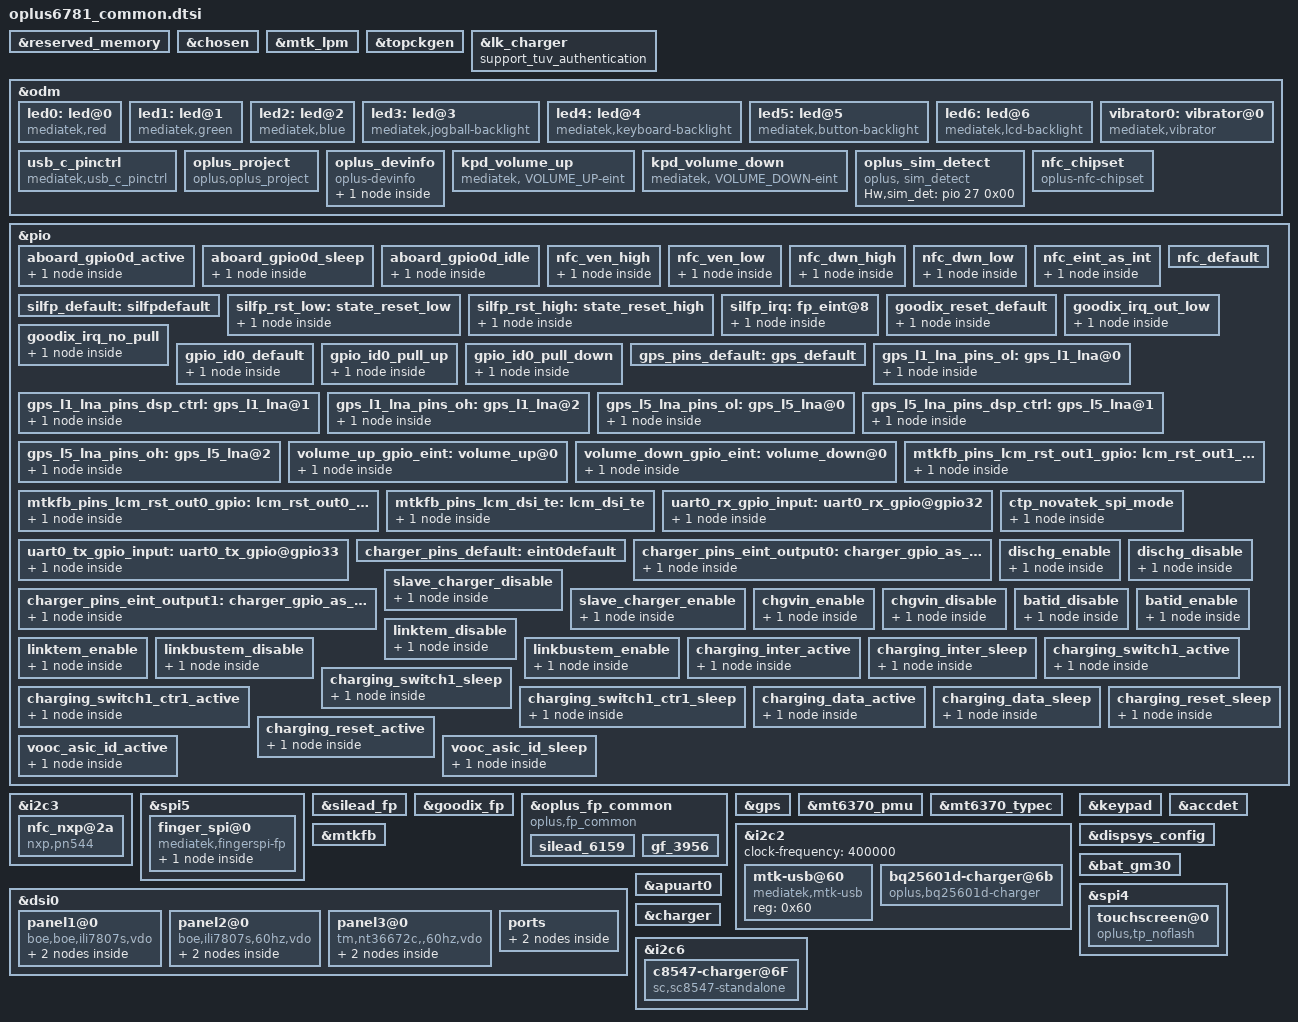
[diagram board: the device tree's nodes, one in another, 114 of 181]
/*
 * Copyright (C) 2015 MediaTek Inc.
 *
 * This program is free software: you can redistribute it and/or modify
 * it under the terms of the GNU General Public License version 2 as
 * published by the Free Software Foundation.
 *
 * This program is distributed in the hope that it will be useful,
 * but WITHOUT ANY WARRANTY; without even the implied warranty of
 * MERCHANTABILITY or FITNESS FOR A PARTICULAR PURPOSE. See the
 * GNU General Public License for more details.
 */
#include <dt-bindings/interrupt-controller/irq.h>
#include <dt-bindings/interrupt-controller/arm-gic.h>
#include <dt-bindings/pinctrl/mt6781-pinfunc.h>

&reserved_memory {
};

/* chosen */
&chosen {
	/* fpga may has no lk, we need to specify display info here */
	/* fb buffer is reserved using this dts by memory node above */
	atag,videolfb-fb_base_l = <0x7e605000>;
	atag,videolfb-fb_base_h = <0x0>;
	atag,videolfb-islcmfound = <1>;
	atag,videolfb-islcm_inited = <0>;
	atag,videolfb-fps= <6000>;
	atag,videolfb-vramSize= <0x017e8000>;
	atag,videolfb-lcmname=
		"nt35695_fhd_dsi_cmd_truly_rt5081_drv";
};

&mtk_lpm {
};

&topckgen {
};

&lk_charger {
	support_tuv_authentication;
};

&odm {
	led0:led@0 {
		compatible = "mediatek,red";
		led_mode = <0>;
		data = <1>;
		pwm_config = <0 0 0 0 0>;
	};
	led1:led@1 {
		compatible = "mediatek,green";
		led_mode = <0>;
		data = <1>;
		pwm_config = <0 0 0 0 0>;
	};
	led2:led@2 {
		compatible = "mediatek,blue";
		led_mode = <0>;
		data = <1>;
		pwm_config = <0 0 0 0 0>;
	};
	led3:led@3 {
		compatible = "mediatek,jogball-backlight";
		led_mode = <0>;
		data = <1>;
		pwm_config = <0 0 0 0 0>;
	};
	led4:led@4 {
		compatible = "mediatek,keyboard-backlight";
		led_mode = <0>;
		data = <1>;
		pwm_config = <0 0 0 0 0>;
	};
	led5:led@5 {
		compatible = "mediatek,button-backlight";
		led_mode = <0>;
		data = <1>;
		pwm_config = <0 0 0 0 0>;
	};
	led6:led@6 {
		compatible = "mediatek,lcd-backlight";
/* wangcheng@MULTIMEDIA.DISPLAY.LCD 2021/06/22 modified for space    pmic control bl   */
/* #ifdef OPLUS_BUG_COMPATIBILITY */
		led_mode = <6>;
/* #endif */
		data = <1>;
		pwm_config = <0 1 0 0 0>;
	};
	vibrator0:vibrator@0 {
		compatible = "mediatek,vibrator";
		/*vib_timer = <25>;
		vib_limit = <9>;
		vib_vol= <9>;*/
		vib_timer = <30>;
		vib_limit = <0>;
		vib_vol= <11>;
	};

	usb_c_pinctrl:usb_c_pinctrl {
		compatible = "mediatek,usb_c_pinctrl";
	};

	oplus_project:oplus_project {
		compatible = "oplus,oplus_project";
	};
	oplus_devinfo:oplus_devinfo {
		compatible = "oplus-devinfo";

		main-sub {
			compatible = "hw-match, main-sub";
			use_tristate_gpio;
			aboard-patterns = <1 2 2 1 1 1 1>;
			aboard-patterns-evt2 = <1 2 2 1 1 2 2>;
			/*main board*/
			match-projects = <21684 21685 21686 21687 21690 21691 21692>;
			aboard-gpio0 = <&pio 165 0x0>;
			pinctrl-names = "aboard_gpio0d_active", "aboard_gpio0d_sleep", "aboard_gpio0d_idle";
			pinctrl-0 = <&aboard_gpio0d_active>;
			pinctrl-1 = <&aboard_gpio0d_sleep>;
			pinctrl-2 = <&aboard_gpio0d_idle>;
		};
	};

	kpd_volume_up:kpd_volume_up {
               compatible = "mediatek, VOLUME_UP-eint";
               interrupt-parent = <&pio>;
               interrupts = <80 IRQ_TYPE_EDGE_FALLING 80 0>;
               debounce = <32000>;
               status = "okay";
       };

	kpd_volume_down:kpd_volume_down {
			compatible = "mediatek, VOLUME_DOWN-eint";
			interrupt-parent = <&pio>;
			interrupts = <81 IRQ_TYPE_EDGE_FALLING 81 0>;
			debounce = <32000>;
			status = "okay";
	};

	//#ifdef OPLUS_FEATURE_TP_BASIC
		oplus_sim_detect {
			compatible = "oplus, sim_detect";
			Hw,sim_det = <&pio 27 0x00>;
		};
	//#endif /* OPLUS_FEATURE_TP_BASIC */

//#ifdef OPLUS_FEATURE_NFC_BRINGUP
    nfc_chipset:nfc_chipset {
        compatible = "oplus-nfc-chipset";
        chipset-21686 = "PN557";
        chipset-21692 = "PN557";
    };
//#endif /* OPLUS_FEATURE_NFC_BRINGUP */
};

&pio {
	aboard_gpio0d_active: aboard_gpio0d_active {
		pins_cmd_dat {
			pinmux = <PINMUX_GPIO165__FUNC_GPIO165>;
			slew-rate = <0>;
			bias-pull-up = <01>;
			input-enable;
		};
	};
	aboard_gpio0d_sleep: aboard_gpio0d_sleep {
		pins_cmd_dat {
			pinmux = <PINMUX_GPIO165__FUNC_GPIO165>;
			slew-rate = <0>;
			bias-pull-up = <00>;
			input-enable;
		};
	};
	aboard_gpio0d_idle: aboard_gpio0d_idle {
		pins_cmd_dat {
			pinmux = <PINMUX_GPIO165__FUNC_GPIO165>;
			slew-rate = <0>;
			bias-disable;
		};
	};
};

//#ifdef OPLUS_FEATURE_NFC_BRINGUP
//ShiHao@CONNECTIVITY.NFC.BASIC , 2021/04/24, add for : add NXP devices
/* NFC GPIO standardization start */
&pio {
    nfc_ven_high: nfc_ven_high {
                pins_cmd_dat {
                        pinmux = <PINMUX_GPIO167__FUNC_GPIO167>;
                        slew-rate = <1>;
                        output-high;
                };
        };
        nfc_ven_low: nfc_ven_low {
                pins_cmd_dat {
                        pinmux = <PINMUX_GPIO167__FUNC_GPIO167>;
                        slew-rate = <1>;
                        output-low;
                };
        };
        nfc_dwn_high: nfc_dwn_high {
                pins_cmd_dat {
                        pinmux = <PINMUX_GPIO56__FUNC_GPIO56>;
                        slew-rate = <1>;
                        output-high;
                };
        };
        nfc_dwn_low: nfc_dwn_low {
                pins_cmd_dat {
                        pinmux = <PINMUX_GPIO56__FUNC_GPIO56>;
                        slew-rate = <1>;
                        output-low;
                };
       };
        nfc_eint_as_int: nfc_eint_as_int {
          pins_cmd_dat {
                        pinmux = <PINMUX_GPIO5__FUNC_GPIO5>;
                        slew-rate = <0>;
                       bias-disable;
                };
        };
        nfc_default: nfc_default {
        };
};

&i2c3 {
       status = "okay";
       nfc_nxp@2a {
               compatible = "nxp,pn544";
               reg = <0x2a>;
               nxp,pn544-irq = <&pio 5 0x0>;
               nxp,pn544-ven = <&pio 167 0x0>;
               nxp,pn544-fw-dwnld = <&pio 56 0x0>;
               interrupt-parent = <&pio>;
       };
};
/* NFC GPIO standardization end */
//#endif /* OPLUS_FEATURE_NFC_BRINGUP */

&spi5 {
	#address-cells = <1>;
	#size-cells = <0>;
	status = "okay";
	finger_spi@0 {
	    compatible = "mediatek,fingerspi-fp";
	    reg = <0>;
	    spi-max-frequency = <8000000>;
	    netlink-event = <30>;
	    spi-id = <1>;
	    spi-irq = <1>;
	    spi-reg = <0x11015000>;
	    irtx_ldo-config = <3000000 3000000 150000>;
        status = "okay";
        power_source_1{
            power-mode = <1>;
            power-name = "irtx_ldo";
            power-config = "irtx_ldo-config";
            delay-time = <0>;
};
    };
};
/*-------------------the silead device config start----------------------*/
&pio {
	silfp_default: silfpdefault {
	};
	silfp_rst_low: state_reset_low {
		pins_cmd_dat {
			pinmux = <PINMUX_GPIO173__FUNC_GPIO173>;
			slew-rate = <1>;
			output-low;
		};
	};
	silfp_rst_high: state_reset_high {
		pins_cmd_dat {
			pinmux = <PINMUX_GPIO173__FUNC_GPIO173>;
			slew-rate = <1>;
			output-high;
		};
	};
	silfp_irq: fp_eint@8 {
		pins_cmd_dat {
			pinmux = <PINMUX_GPIO1__FUNC_GPIO1>;
			slew-rate = <0>;
			bias-disable;
		};
	};
};
&silead_fp {
	sil,silead_irq = <&pio 1 0x00>;
	sil,ldo_disable = <0>;
	sil,vmch_enable = <2>;
	pinctrl-names = "default", "rst-low", "rst-high",
	                "irq-init";
	pinctrl-0 = <&silfp_default>;
	pinctrl-1 = <&silfp_rst_low>;
	pinctrl-2 = <&silfp_rst_high>;
	pinctrl-3 = <&silfp_irq>;
	status = "okay";
};
/*-------------------the silead device config end----------------------*/

&pio {
	goodix_reset_default: goodix_reset_default {
		pins_cmd_dat {
			pinmux = <PINMUX_GPIO173__FUNC_GPIO173>;
			slew-rate = <1>;
			output-low;
		};
	};
	goodix_irq_out_low: goodix_irq_out_low {
		pins_cmd_dat {
			pinmux = <PINMUX_GPIO1__FUNC_GPIO1>;
			slew-rate = <1>;
			output-low;
		};
	};
	goodix_irq_no_pull: goodix_irq_no_pull {
		pins_cmd_dat {
			pinmux = <PINMUX_GPIO1__FUNC_GPIO1>;
			slew-rate = <0>;
			bias-disable;
		};
	};
};

&goodix_fp {
	pinctrl-names = "goodix_reset_default", "goodix_irq_out_low", "goodix_irq_no_pull";
	pinctrl-0 = <&goodix_reset_default>;
	pinctrl-1 = <&goodix_irq_out_low>;
	pinctrl-2 = <&goodix_irq_no_pull>;
	interrupt-parent = <&pio>;
	interrupts = <1 0>;
	goodix,gpio_irq = <&pio 1 0x00>;
	goodix,gpio_reset = <&pio 173 0x00>;
	gf,cs_gpio_disable = <1>;
	spi-max-frequency = <8000000>;
	status = "okay";
};

/*the finger_id config to project dts.*/

&pio{
	gpio_id0_default: gpio_id0_default {
		pins_cmd_dat {
			pinmux = <PINMUX_GPIO170__FUNC_GPIO170>;
			slew-rate = <0>;
			bias-pull-up = <00>;
		};
	};
	gpio_id0_pull_up: gpio_id0_pull_up {
		pins_cmd_dat {
			pinmux = <PINMUX_GPIO170__FUNC_GPIO170>;
			slew-rate = <0>;
			bias-pull-up = <00>;
		};
	};
	gpio_id0_pull_down: gpio_id0_pull_down {
		pins_cmd_dat {
			pinmux = <PINMUX_GPIO170__FUNC_GPIO170>;
			slew-rate = <0>;
			bias-pull-down = <00>;
		};
	};
};

&oplus_fp_common {
	compatible = "oplus,fp_common"; //Manufacture, and Model
	oplus,fp_gpio_num = <1>;
	oplus,fp_gpio_0 = <&pio 170 0x00>;
	pinctrl-names = "gpio_id0_default", "gpio_id0_pull_up", "gpio_id0_pull_down";
	pinctrl-0 = <&gpio_id0_default>;
	pinctrl-1 = <&gpio_id0_pull_up>;
	pinctrl-2 = <&gpio_id0_pull_down>;

    silead_6159 {
            oplus,fp-id = <0>; /* fp id mapping table */
            vendor-chip = <19>; /* please refer to the struct fp_vendor_t in oplus_fp_commmon.n */
            eng-menu = "-1,-1"; /* represents SNR, inclination test item in engineer menu, and 0/1 means off/on */
            chip-name = "S_gsl6159";  /* /proc/fp_id, will be displayed in engineer menu  */
    };
    gf_3956 {
            oplus,fp-id = <1>; /* fp id mapping table */
            vendor-chip = <20>; /* please refer to the struct fp_vendor_t in oplus_fp_commmon.n */
            eng-menu = "-1,-1"; /* represents SNR, inclination test item in engineer menu, and 0/1 means off/on */
            chip-name = "G_3956";  /* /proc/fp_id, will be displayed in engineer menu  */
    };
};

/* GPS GPIO standardization start */
&pio {
	gps_pins_default: gps_default {
	};

	gps_l1_lna_pins_ol: gps_l1_lna@0 {
		pins_cmd_dat {
			pinmux = <PINMUX_GPIO172__FUNC_GPIO172>;
			output-low;
		};
	};
	gps_l1_lna_pins_dsp_ctrl: gps_l1_lna@1 {
		pins_cmd_dat {
			pinmux = <PINMUX_GPIO172__FUNC_GPS_L1_ELNA_EN>;
		};
	};
	gps_l1_lna_pins_oh: gps_l1_lna@2 {
		pins_cmd_dat {
			pinmux = <PINMUX_GPIO172__FUNC_GPIO172>;
			output-high;
		};
	};

	gps_l5_lna_pins_ol: gps_l5_lna@0 {
		pins_cmd_dat {
			pinmux = <PINMUX_GPIO173__FUNC_GPIO173>;
			output-low;
		};
	};
	gps_l5_lna_pins_dsp_ctrl: gps_l5_lna@1 {
		pins_cmd_dat {
			pinmux = <PINMUX_GPIO173__FUNC_GPS_L5_ELNA_EN>;
		};
	};
	gps_l5_lna_pins_oh: gps_l5_lna@2 {
		pins_cmd_dat {
			pinmux = <PINMUX_GPIO173__FUNC_GPIO173>;
			output-high;
		};
	};
};

&gps {
	pinctrl-names = "default",
		"gps_l1_lna_disable",
		"gps_l1_lna_dsp_ctrl",
		"gps_l1_lna_enable",
		"gps_l5_lna_disable",
		"gps_l5_lna_dsp_ctrl",
		"gps_l5_lna_enable";
	pinctrl-0 = <&gps_pins_default>;
	pinctrl-1 = <&gps_l1_lna_pins_ol>;
	pinctrl-2 = <&gps_l1_lna_pins_dsp_ctrl>;
	pinctrl-3 = <&gps_l1_lna_pins_oh>;
	pinctrl-4 = <&gps_l5_lna_pins_ol>;
	pinctrl-5 = <&gps_l5_lna_pins_dsp_ctrl>;
	pinctrl-6 = <&gps_l5_lna_pins_oh>;
	status = "okay";
};
/* GPS GPIO standardization end */

&mt6370_pmu {
	mt6370,intr_gpio_num = <4>; /* direct defined GPIO num */
	mt6370,intr_gpio = <&pio 4 0x0>;
};

&mt6370_typec {
	mt6370pd,intr_gpio_num = <83>; /* direct defined GPIO num */
	mt6370pd,intr_gpio = <&pio 83 0x0>;
};

&i2c2 {
	clock-frequency = <400000>;
	mtk-usb@60 {
		compatible = "mediatek,mtk-usb";
		reg = <0x60>;
		status = "okay";
	};
	bq25601d-charger@6b {
		status = "okay";
		compatible = "oplus,bq25601d-charger";
		reg = <0x6b>;
		chip-name = "BQ25601D";
		interrupt-parent = <&pio>;
		interrupts = <42 IRQ_TYPE_EDGE_FALLING 42 0>;
		chg-irq-gpio = <&pio 42 0x2002>;

		pinctrl-names = "slave_charger_enable", "slave_charger_disable";
		pinctrl-0 = <&slave_charger_enable>;
		pinctrl-1 = <&slave_charger_disable>;

		qcom,slave-chg-en-gpio = <&pio 6 0x00>;
	};
};

&keypad {
	keypad,volume-up	= <&pio 80 0x00>;
	keypad,volume-down	= <&pio 81 0x00>;
	pinctrl-names = "volume_up_as_int", "volume_down_as_int";
	pinctrl-0 = <&volume_up_gpio_eint>;
	pinctrl-1 = <&volume_down_gpio_eint>;
	status = "okay";
};

&pio {
	volume_up_gpio_eint:volume_up@0{
		pins_cmd_dat {
			pinmux = <PINMUX_GPIO80__FUNC_GPIO80>;
			slew-rate = <0>;  /*direction 0:in, 1:out*/
			bias-pull-up = <00>;
			input-enable;
		};
	};
	volume_down_gpio_eint:volume_down@0{
		pins_cmd_dat {
			pinmux = <PINMUX_GPIO81__FUNC_GPIO81>;
			slew-rate = <0>;  /*direction 0:in, 1:out*/
			bias-pull-up = <01>;
			input-enable;
		};
	};
};

/* accdet start */
&accdet {
	/* accdet micbias voltage: 0x07,2.7v;0x05,2.5v;0x02,1.9v */
	accdet-mic-vol = <7>;
	headset-mode-setting = <0x500 0x500 1 0x1f0 0x800 0x800 0x20 0x44>;
	accdet-plugout-debounce = <1>;
	/*1:ACC mode, 2:low cost without in bias, 6:low cost with in bias*/
	accdet-mic-mode = <1>;
	/* eint_level_trigger: 8,LEVEL_LOW(DEF) ;4,LV_HIGH;others,LV_LOW */
	headset-eint-level-pol = <8>;
	/*0--MD_MAX--UP_MAX--DW_MAX*/
	headset-three-key-threshold = <0 80 220 400>;
	headset-three-key-threshold-CDD = <0 121 192 600>;
	/*0--MD_MAX--VOICE_MAX--UP_MAX--DW_MAX*/
	headset-four-key-threshold = <0 58 121 192 400>;
	status = "okay";
};
/* accdet end */

#ifndef CONFIG_FPGA_EARLY_PORTING
&pio {
	mtkfb_pins_lcm_rst_out1_gpio: lcm_rst_out1_gpio {
		pins_cmd_dat {
			pinmux = <PINMUX_GPIO99__FUNC_GPIO99>;
			slew-rate = <1>;
			output-high;
		};
	};

	mtkfb_pins_lcm_rst_out0_gpio: lcm_rst_out0_gpio {
		pins_cmd_dat {
			pinmux = <PINMUX_GPIO99__FUNC_GPIO99>;
			slew-rate = <1>;
			output-low;
		};
	};
	mtkfb_pins_lcm_dsi_te: lcm_dsi_te {
		pins_cmd_dat {
			pinmux = <PINMUX_GPIO97__FUNC_DSI_TE>;
		};
	};
};

&mtkfb {
	pinctrl-names = "lcm_rst_out1_gpio", "lcm_rst_out0_gpio",
		"mode_te_te";
	pinctrl-0 = <&mtkfb_pins_lcm_rst_out1_gpio>;
	pinctrl-1 = <&mtkfb_pins_lcm_rst_out0_gpio>;
	pinctrl-2 = <&mtkfb_pins_lcm_dsi_te>;
	status = "okay";
};

&dispsys_config {
	pinctrl-names =
		"lcm_rst_out1_gpio", "lcm_rst_out0_gpio",
		"mode_te_te";
	pinctrl-0 = <&mtkfb_pins_lcm_rst_out1_gpio>;
	pinctrl-1 = <&mtkfb_pins_lcm_rst_out0_gpio>;
	pinctrl-2 = <&mtkfb_pins_lcm_dsi_te>;
	status = "okay";
};

&dsi0 {
	status = "okay";
	#address-cells = <1>;
	#size-cells = <0>;
	panel1@0 {
		compatible = "boe,boe,ili7807s,vdo";
		reg = <0>;
		reset-gpios = <&pio 99 0>;
		pinctrl-names = "default";
		port {
			panel_in1: endpoint {
				remote-endpoint = <&dsi_out>;
			};
		};
	};
    panel2@0 {
		compatible = "boe,ili7807s,60hz,vdo";
		reg = <1>;
		reset-gpios = <&pio 99 0>;
		pinctrl-names = "default";
		port {
			panel_in2: endpoint {
				remote-endpoint = <&dsi_out>;
			};
		};
	};
    panel3@0 {
		compatible = "tm,nt36672c,,60hz,vdo";
		reg = <2>;
		reset-gpios = <&pio 99 0>;
		pinctrl-names = "default";
		port {
			panel_in3: endpoint {
				remote-endpoint = <&dsi_out>;
			};
		};
	};
	ports {
		port {
			dsi_out: endpoint {
				remote-endpoint = <&panel_in1>;
			};
		};
	};
};

#endif

&bat_gm30 {
       FUELGAGUE_APPLY = <(1)>;
       ENABLE_IS_FORCE_FULL = <1>;
       R_FG_VALUE = <(5)>;
/*#ifdef OPLUS_FEATURE_CHG_BASIC*/
        io-channels = <&auxadc 2>;
        io-channel-names = "auxadc2-batt_id_v";
        #include "mediatek/bat_setting/mt6833_battery_table_ext.dtsi"
        #include "mediatek/bat_setting/mt6833_battery_prop_dim2_ext.dtsi"
/*#endif OPLUS_FEATURE_CHG_BASIC*/

	qcom,batid-gpio = <&pio 51 0x00>;
	qcom,linktem-gpio = <&pio 41 0x00>;
	qcom,linkbustem-gpio = <&pio 49 0x00>;
	pinctrl-names = "batid_disable","batid_enable","linktem_disable","linktem_enable","linkbustem_disable","linkbustem_enable";
	pinctrl-0 = <&batid_disable>;
	pinctrl-1= <&batid_enable>;
	pinctrl-2= <&linktem_disable>;
	pinctrl-3 = <&linktem_enable>;
	pinctrl-4 = <&linkbustem_disable>;
	pinctrl-5 = <&linkbustem_enable>;

};


/* TOUCH start */
&spi4 {
	status = "okay";

	 touchscreen@0 {
		compatible = "oplus,tp_noflash";
		reg = <0>; //Same as CS ID
		chip-name = "NF_ILI7807S";
		status = "okay";

		spi-max-frequency = <9600000>;
		interrupt-parent = <&pio>;
		interrupts = <12 IRQ_TYPE_EDGE_FALLING 12 0>;
		irq-gpio = <&pio 12 0x2002>;
		reset-gpio = <&pio 121 0>;

		platform_support_project = <21684 21685 21686 21687 21690 21691 21692>;
		platform_support_project_dir = <21684 21685 21686 21687 21690 21691 21692>;
		platform_support_project_commandline = "default_commandline","default_commandline","default_commandline","default_commandline","default_commandline","default_commandline","default_commandline";

		touchpanel,max-num-support = <10>;
		touchpanel,tx-rx-num = <18 36>;
		touchpanel,panel-coords = <1080 2412>;
		touchpanel,display-coords = <1080 2412>;
		touchpanel,touchmajor-limit = <0 54>;
		pinctrl-names = "default","pin_set_low", "pin_set_high";
		pinctrl-0 = <&ctp_novatek_spi_mode>;

		prevention,dead_area_width = <20 20>;
		prevention,condition_area_width = <60 60 160 160>;
		prevention,eli_area_width = <240 1000 1200 240>;

		incell_screen;
		irq_need_dev_resume_ok;
		fw_edge_limit_support;
		black_gesture_support;
		charger_pump_support;
		headset_pump_support;
		esd_handle_support;
		black_gesture_test_support;
		game_switch_support;
		noflash_support;
		lcd_trigger_load_tp_fw_support;
		smart_gesture_support;
		pressure_report_support;
		fw_update_app_support;
		health_monitor_v2_support;
		touchpanel,button-type = <4>;
	};
};

&apuart0 {
        pinctrl-names = "uart0_rx_gpio",
                        "uart0_tx_gpio";
        pinctrl-0 = <&uart0_rx_gpio_input>;
        pinctrl-1 = <&uart0_tx_gpio_input>;
        status = "okay";
};

&pio {
        uart0_rx_gpio_input:uart0_rx_gpio@gpio32 {
                pins_cmd_dat {
                        pinmux = <PINMUX_GPIO32__FUNC_GPIO32>;
                        input-enable;
                        slew-rate = <0>;
                        bias-disable;
                };
        };
        uart0_tx_gpio_input:uart0_tx_gpio@gpio33 {
                pins_cmd_dat {
                        pinmux = <PINMUX_GPIO33__FUNC_GPIO33>;
                        input-enable;
                        slew-rate = <0>;
                        bias-disable;
                };
        };
};

&pio {
	ctp_novatek_spi_mode:ctp_novatek_spi_mode{
		pins_cmd_dat {
			pinmux = <PINMUX_GPIO14__FUNC_SPI4_MI>,
				<PINMUX_GPIO13__FUNC_SPI4_MO>,
				<PINMUX_GPIO144__FUNC_SPI4_CLK>,
				<PINMUX_GPIO145__FUNC_SPI4_CSB>;
			drive-strength = <4>;
		};
	};
};
/* TOUCH end */
&charger {
	io-channels = /*<&auxadc 2>,*/<&auxadc 3>,<&auxadc 4>,
		<&auxadc 5>;
	io-channel-names = /*"auxadc2-batid_linktemp",*/"auxadc3-usb_temp_v_l","auxadc4-flashlight_temp",
		"auxadc5-usb_temp_v_r";

	pinctrl-names = "default", "charger_gpio_as_output_low", "charger_gpio_as_output_high",
					/*"ship_sleep", "ship_active",*/ "dischg_enable", "dischg_disable", "chgvin_enable", "chgvin_disable";
					/*"state_uart0_rx_output0","state_uart0_tx_output0";*/
	pinctrl-0 = <&charger_pins_default>;
	pinctrl-1 = <&charger_pins_eint_output0>;
	pinctrl-2 = <&charger_pins_eint_output1>;
	//pinctrl-3 = <&ship_sleep_gpio>;
	//pinctrl-4 = <&ship_active_gpio>;
	pinctrl-3 = <&dischg_enable>;
	pinctrl-4 = <&dischg_disable>;
	pinctrl-5 = <&chgvin_enable>;
	pinctrl-6 = <&chgvin_disable>;
	//pinctrl-7 = <&uart0_rx_output0>;
	//pinctrl-8 = <&uart0_tx_output0>;
	//pinctrl-5 = <&shortc_active_gpio>;

	//for oplus chg framework:
	qcom,pd_input_current_charger_ma = <3350>;
	qcom,input_current_charger_ma = <2200>;
	qcom,input_current_usb_ma = <650>;

	qcom,vooc_show_ui_soc_decimal;

	qcom,vbatt_pdqc_to_9v_thr = <4200>;
	qcom,vbatt_pdqc_to_5v_thr = <4100>;
	qcom,input_current_led_ma = <1200>;
	qcom,input_current_led_ma_high = <1200>;
	qcom,input_current_led_ma_warm = <1500>;
	qcom,input_current_led_ma_normal = <3350>;
	qcom,led_warm_bat_decidegc = <350>;
	qcom,led_high_bat_decidegc = <370>;
	qcom,input_current_led_ma_forcmcc = <500>;

	qcom,input_current_camera_ma = <1200>;
	qcom,input_current_calling_ma = <1500>;
	qcom,qc_input_current_charger_ma = <2000>;
	qcom,ui_soc_decimal_speedmin = <20>;//2A
	qcom,input_current_cdp_ma = <1800>;
	qcom,overtemp_bat_decidegc = <350>;
	qcom,iterm_disabled = <0>;
	sw_full_count = <25>;
	qcom,iterm_ma = <270>;
	qcom,iterm_ma3 = <270>;
	qcom,recharge-mv = <100>;

	qcom,batt_capacity_mah = <5000>; /*typical capacity*/
	//qcom,batt_capacity_mah = <3920>; /*rated capacity*/

	qcom,usb_high_than_bat_decidegc = <168>;

	qcom,removed_bat_decidegc = <190>;  /* < -19C */

	qcom,cold_bat_decidegc = <20>;  /* -3C ~ 0C */
	qcom,temp_cold_vfloat_mv = <3980>;
	qcom,temp_cold_fastchg_current_ma = <360>;

	qcom,little_cold_bat_decidegc = <0>;	/* 0C ~ 5C */
	qcom,temp_little_cold_vfloat_mv = <4435>;
	qcom,temp_little_cold_fastchg_current_ma_high = <2200>;
	qcom,temp_little_cold_fastchg_current_ma_low = <1400>;
	qcom,pd_temp_little_cold_fastchg_current_ma_high = <2350>;
	qcom,pd_temp_little_cold_fastchg_current_ma_low = <1400>;
	qcom,qc_temp_little_cold_fastchg_current_ma_high = <2350>;
	qcom,qc_temp_little_cold_fastchg_current_ma_low = <1400>;
	qcom,temp_little_cold_fastchg_current_ma = <1400>;

	qcom,cool_bat_decidegc = <50>;	/* 5C ~ 12C */
	qcom,temp_cool_vfloat_mv = <4435>;
	qcom,temp_cool_fastchg_current_ma_high = <2200>;
	qcom,temp_cool_fastchg_current_ma_low = <2200>;
	qcom,pd_temp_cool_fastchg_current_ma_high = <2300>;
	qcom,pd_temp_cool_fastchg_current_ma_low = <2300>;
	qcom,qc_temp_cool_fastchg_current_ma_high = <2300>;
	qcom,qc_temp_cool_fastchg_current_ma_low = <2300>;

	qcom,little_cool_bat_decidegc = <120>;	/* 12C ~ 16C */
	qcom,temp_little_cool_vfloat_mv = <4435>;
	qcom,temp_little_cool_fastchg_current_ma = <2200>;
	qcom,pd_temp_little_cool_fastchg_current_ma = <3350>;
	qcom,pd_temp_little_cool_fastchg_current_ma_low = <2300>;
	qcom,temp_little_cool_fastchg_current_ma_low = <1700>;
	qcom,qc_temp_little_cool_fastchg_current_ma = <3350>;
	qcom,qc_temp_little_cool_fastchg_current_ma_high = <3350>;
	qcom,qc_temp_little_cool_fastchg_current_ma_low = <2300>;

	qcom,normal_bat_decidegc = <160>;	/* 16C ~ 45C */
	qcom,temp_normal_fastchg_current_ma = <2200>;
	qcom,temp_normal_vfloat_mv = <4435>;
	qcom,pd_temp_normal_fastchg_current_ma = <3350>;
	qcom,qc_temp_normal_fastchg_current_ma = <3350>;

	qcom,normal_phase1_bat_decidegc = <160>;       /* 16C ~ 22C */
	qcom,temp_normal_phase1_vfloat_mv = <4435>;
	qcom,temp_normal_phase1_fastchg_current_ma = <3350>;

	qcom,normal_phase2_bat_decidegc = <220>;       /* 22C ~ 34C */
	qcom,temp_normal_phase2_vfloat_mv = <4435>;
	qcom,temp_normal_phase2_fastchg_current_ma_high = <3350>;
	qcom,temp_normal_phase2_fastchg_current_ma_low = <3350>;

	qcom,normal_phase3_bat_decidegc = <340>;       /* 34 ~ 37C */
	qcom,temp_normal_phase3_vfloat_mv = <4435>;
	qcom,temp_normal_phase3_fastchg_current_ma_high = <2850>;
	qcom,temp_normal_phase3_fastchg_current_ma_low = <2850>;

	qcom,normal_phase4_bat_decidegc = <370>;       /* 37C ~ 40C */
	qcom,temp_normal_phase4_vfloat_mv = <4435>;
	qcom,temp_normal_phase4_fastchg_current_ma_high = <2600>;
	qcom,temp_normal_phase4_fastchg_current_ma_low = <2600>;

	qcom,normal_phase5_bat_decidegc = <400>;       /* 40C ~ 42C */
	qcom,temp_normal_phase5_vfloat_mv = <4435>;
	qcom,temp_normal_phase5_fastchg_current_ma = <2300>;

	qcom,normal_phase6_bat_decidegc = <420>;       /* 42C ~ 45C */
	qcom,temp_normal_phase6_vfloat_mv = <4435>;
	qcom,temp_normal_phase6_fastchg_current_ma = <1400>;

	qcom,warm_bat_decidegc = <450>;		/* 45C ~ 53C */ /*8pin Bat Vooc project need add 3 degree C*/
	qcom,temp_warm_vfloat_mv = <4130>;
	qcom,temp_warm_fastchg_current_ma = <1400>;
	qcom,temp_warm_fastchg_current_ma3 = <1300>;
	qcom,pd_temp_warm_fastchg_current_ma = <1400>;
	qcom,qc_temp_warm_fastchg_current_ma = <1400>;
	qcom,temp_warm_fastchg_current_ma_led_on = <500>;

	qcom,hot_bat_decidegc = <530>;  /* > 53C */

	qcom,non_standard_vfloat_mv = <3980>;
	qcom,non_standard_fastchg_current_ma = <512>;

	qcom,short_c_bat_cv_mv = <4330>;
	qcom,short_c_bat_vfloat_mv = <3800>;
	qcom,short_c_bat_fastchg_current_ma = <512>;
	qcom,short_c_bat_vfloat_sw_limit = <3750>;

	qcom,cold_vfloat_sw_limit = <3930>;
	qcom,little_cold_vfloat_sw_limit = <4385>;
	qcom,cool_vfloat_sw_limit = <4385>;
	qcom,little_cool_vfloat_sw_limit = <4385>;
	qcom,normal_vfloat_sw_limit = <4385>;
	qcom,warm_vfloat_sw_limit = <4080>;
	qcom,non_standard_vfloat_sw_limit = <3930>;

	qcom,max_chg_time_sec = <58700>;//20h
	qcom,charger_hv_thr = <10000>;
	qcom,charger_lv_thr = <3400>;
	qcom,vbatt_full_thr = <4400>;
	qcom,vbatt_hv_thr = <4550>;
	qcom,charger_recv_thr = <9700>;

	qcom,vfloat_step_mv = <5>;
	qcom,non_standard_vfloat_over_sw_limit = <3990>;
	qcom,cold_vfloat_over_sw_limit = <3990>;
	qcom,little_cold_vfloat_over_sw_limit = <4445>;
	qcom,cool_vfloat_over_sw_limit = <4445>;
	qcom,little_cool_vfloat_over_sw_limit = <4445>;
	qcom,normal_vfloat_over_sw_limit = <4445>;
	qcom,warm_vfloat_over_sw_limit = <4140>;

	qcom,vbatt_power_off = <3300>;
	qcom,vbatt_soc_1 = <3410>;
	qcom,vooc_project = <5>;
	qcom,vbatt_num = <1>;

	qcom,normal_vterm_hw_inc = <18>;
	qcom,non_normal_vterm_hw_inc = <18>;

	qcom,ff1_normal_fastchg_ma = <1500>;
	qcom,ff1_exit_step_ma = <600>;
	qcom,ff1_warm_exit_step_ma = <500>;
	qcom,ffc2_normal_fastchg_ma = <1200>;/*12C~35c*/
	qcom,ffc2_temp_warm_decidegc = <350>;
	qcom,ffc2_warm_fastchg_ma = <1300>;/*35C~40c*/
	qcom,ffc2_temp_high_decidegc = <400>;
	qcom,ffc2_temp_low_decidegc = <120>;
	qcom,ffc2_exit_step_ma = <150>;

	qcom,ffc_normal_vfloat_sw_limit = <4475>;
	qcom,ffc_normal_vfloat_sw_limit3 = <4475>;
	qcom,ffc_temp_normal_vfloat_mv = <4550>;
	qcom,ffc_normal_vfloat_over_sw_limit = <4550>;

	qcom,default_iterm_ma = <270>;
	qcom,default_iterm_ma3 = <270>;
	qcom,default_temp_normal_fastchg_current_ma = <2200>;
	qcom,default_normal_vfloat_sw_limit = <4385>;
	qcom,default_temp_normal_vfloat_mv = <4435>;
	qcom,default_normal_vfloat_over_sw_limit = <4445>;

	qcom,default_temp_little_cool_fastchg_current_ma = <2200>;
	qcom,default_little_cool_vfloat_sw_limit = <4385>;
	qcom,default_temp_little_cool_vfloat_mv = <4435>;
	qcom,default_little_cool_vfloat_over_sw_limit = <4445>;

	//for control:
	//qcom,suspend_after_full;
	qcom,chg_ctrl_by_calling;
	qcom,check_batt_full_by_sw;
	qcom,external_gauge;
	qcom,chg_ctrl_by_lcd;
	qcom,chg_ctrl_by_camera;
	qcom,sw_vfloat_over_protect_enable;
	qcom,ffc_support;
	qcom,chargerid_vol_disable;
	qcom,support_ntc_01c_precision;
	qcom,fg_error_check;
	qcom,voocphy_support;
	qcom,hv_flashled_support;
	//qcom,dual_charger_support
	qcom,slave_pct = <30>;
	qcom,slave_chg_enable_ma = <1000>;
	qcom,slave_chg_disable_ma = <700>;
	//GPIO config:
	qcom,chargerid_switch-gpio = <&pio 36 0x00>;
	//qcom,ship-gpio = <&pio 69 0x00>;
	qcom,dischg-gpio = <&pio 15 0x00>;
	//qcom,shortc-gpio = <&pio 121 0x00>;
	qcom,chgvin = <&pio 3 0x00>;
	qcom,batid-gpio = <&pio 51 0x00>;
};

&i2c6 {
	c8547-charger@6F{
		status = "okay";
                compatible = "sc,sc8547-standalone";
                reg = <0x6F 0>;

                qcom,switch_voocphy_irq_gpio = <&pio 7 0x00>;
                interrupt-parent = <&pio>;
                interrupts = <7 0>;

                sc,sc8547,bat-ovp-disale = <1>;
                sc,sc8547,vdrop-ovp-disale = <1>;
                sc,sc8547,bus-ovp-disale = <1>;
                sc,sc8547,bus-ucp-disale = <1>;
                sc,sc8547,bus-ocp-disale = <1>;

                sc,sc8547,bat-ovp-threshold = <4525>;/*mv*/
                sc,sc8547,bat-ocp-threshold = <7000>;/*mv*/
                sc,sc8547,ac-ovp-threshold = <13000>;/*mv*/
                sc,sc8547,bus-ovp-threshold = <11000>;/*mv*/
                sc,sc8547,bus-ocp-threshold = <3500>;/*ma*/
                sc,sc8547,sense-resistor-mohm = <5>;/*m|?*/

                qcom,voocphy_freq_mincore = <1860000>;
                qcom,voocphy_freq_midcore = <1923000>;
                qcom,voocphy_freq_maxcore = <1986000>;
                qcom,voocphy_current_change_timeout = <100>;

		pinctrl-names = "switch1_act_switch2_act", "switch1_sleep_switch2_sleep",
					"charging_inter_active", "charging_inter_sleep";
		pinctrl-0 = <&charging_switch1_active>;
        pinctrl-1 = <&charging_switch1_sleep>;
		pinctrl-2 = <&charging_inter_active>;
        pinctrl-3 = <&charging_inter_sleep>;

		qcom,charging_switch1-gpio = <&pio 37 0x00>;
	};
};

&pio {
	charger_pins_default: eint0default {
	};
	charger_pins_eint_output0: charger_gpio_as_output_low {
		pins_cmd_dat {
			pinmux = <PINMUX_GPIO36__FUNC_GPIO36>;
			slew-rate = <1>;
			output-low;
		};
	};
	charger_pins_eint_output1: charger_gpio_as_output_high {
		pins_cmd_dat {
			pinmux = <PINMUX_GPIO36__FUNC_GPIO36>;
			slew-rate = <1>;
			output-high;
		};
	};

	/*ship_sleep_gpio: ship_sleep {
		pins_cmd_dat {
			pinmux = <PINMUX_GPIO69__FUNC_GPIO69>;
			slew-rate = <1>;
			output-low;
		};
	};
	ship_active_gpio: ship_active {
		pins_cmd_dat {
			pinmux = <PINMUX_GPIO69__FUNC_GPIO69>;
			slew-rate = <1>;
			output-high;
		};
	};*/

	dischg_enable: dischg_enable {
		pins_cmd_dat {
			pinmux = <PINMUX_GPIO15__FUNC_GPIO15>;
			slew-rate = <1>;//0:input direction 1:output direction
			bias-pull-up = <00>;
			output-high;
		};
	};

	dischg_disable: dischg_disable {
		pins_cmd_dat {
			pinmux = <PINMUX_GPIO15__FUNC_GPIO15>;
			slew-rate = <1>;
			bias-pull-down = <00>;
			output-low;
		};
	};

	slave_charger_disable: slave_charger_disable {
        pins_cmd_dat {
            pinmux = <PINMUX_GPIO6__FUNC_GPIO6>;
            slew-rate = <1>;//0:input direction 1:output direction
            bias-pull-up = <00>;
            output-low;
        };
    };

    slave_charger_enable: slave_charger_enable {
        pins_cmd_dat {
            pinmux = <PINMUX_GPIO6__FUNC_GPIO6>;
            slew-rate = <1>;
            bias-pull-down = <00>;
            output-high;
        };
    };

    chgvin_enable: chgvin_enable {
        pins_cmd_dat {
            pinmux = <PINMUX_GPIO3__FUNC_GPIO3>;
            slew-rate = <1>;//0:input direction 1:output direction
            bias-pull-up = <00>;
            output-low;
        };
    };
    chgvin_disable: chgvin_disable {
        pins_cmd_dat {
            pinmux = <PINMUX_GPIO3__FUNC_GPIO3>;
            slew-rate = <1>;
            bias-pull-down = <00>;
            output-high;
        };
    };
/*
	uart0_rx_output0:uart0_rx_gpio@gpio32 {
		pins_cmd_dat {
			pinmux = <PINMUX_GPIO32__FUNC_GPIO32>;
			slew-rate = <1>;
			output-low;
		};
	};
	uart0_tx_output0:uart0_tx_gpio@gpio33 {
		pins_cmd_dat {
			pinmux = <PINMUX_GPIO33__FUNC_GPIO33>;
			slew-rate = <1>;
			output-low;
		};
	};
*/
/*
	shortc_active_gpio: shortc_active {
		pins_cmd_dat {
			pinmux = <PINMUX_GPIO121__FUNC_GPIO121>;
			input-enable;
			slew-rate = <0>;
			bias-pull-up;
		};
	};
*/

    batid_disable: batid_disable {
        pins_cmd_dat {
            pinmux = <PINMUX_GPIO51__FUNC_GPIO51>;
            slew-rate = <1>;//0:input direction 1:output direction
            bias-pull-up= <00>;
            output-low;
        };
    };
        batid_enable: batid_enable {
        pins_cmd_dat {
            pinmux = <PINMUX_GPIO51__FUNC_GPIO51>;
            slew-rate = <1>;//0:input direction 1:output direction
            bias-pull-down = <00>;
            output-high;
        };
    };

        linktem_disable: linktem_disable {
        pins_cmd_dat {
            pinmux = <PINMUX_GPIO41__FUNC_GPIO41>;
            slew-rate = <1>;//0:input direction 1:output direction
            bias-pull-up = <00>;
            output-low;
        };
    };
        linktem_enable: linktem_enable {
        pins_cmd_dat {
            pinmux = <PINMUX_GPIO41__FUNC_GPIO41>;
            slew-rate = <1>;//0:input direction 1:output direction
            bias-pull-down = <00>;
            output-high;
        };
    };

        linkbustem_disable: linkbustem_disable {
        pins_cmd_dat {
            pinmux = <PINMUX_GPIO49__FUNC_GPIO49>;
            slew-rate = <1>;
            bias-pull-up = <00>;
            output-low;
        };
    };

            linkbustem_enable: linkbustem_enable {
        pins_cmd_dat {
            pinmux = <PINMUX_GPIO49__FUNC_GPIO49>;
            slew-rate = <1>;
            bias-pull-down = <00>;
            output-high;
        };
    };
};

&pio {
	charging_inter_active: charging_inter_active {
		pins_cmd_dat {
                        pinmux = <PINMUX_GPIO7__FUNC_GPIO7>;
                        slew-rate = <0>;
			bias-pull-up = <00>;
                        //output-high;
                };
             };
	charging_inter_sleep: charging_inter_sleep {
		pins_cmd_dat {
                        pinmux = <PINMUX_GPIO7__FUNC_GPIO7>;
                        slew-rate = <0>;
			bias-pull-up = <00>;
                        //output-low;
                };
            };
	charging_switch1_active: charging_switch1_active {
		pins_cmd_dat {
			pinmux = <PINMUX_GPIO37__FUNC_GPIO37>;
			slew-rate = <1>;
			output-high;
		};
	};
	charging_switch1_sleep: charging_switch1_sleep {
		pins_cmd_dat {
			pinmux = <PINMUX_GPIO37__FUNC_GPIO37>;
			slew-rate = <1>;
			output-low;
		};
	};
	
	charging_switch1_ctr1_active: charging_switch1_ctr1_active {
		pins_cmd_dat {
			pinmux = <PINMUX_GPIO148__FUNC_GPIO148>;
			slew-rate = <1>;
			output-high;
		};
	};
	charging_switch1_ctr1_sleep: charging_switch1_ctr1_sleep {
		pins_cmd_dat {
			pinmux = <PINMUX_GPIO148__FUNC_GPIO148>;
			slew-rate = <1>;
			output-low;
		};
	};
	charging_data_active: charging_data_active {
		pins_cmd_dat {
			pinmux = <PINMUX_GPIO14__FUNC_GPIO14>;
			slew-rate = <0>;
			bias-pull-up = <00>;
		};
	};
	charging_data_sleep: charging_data_sleep {
		pins_cmd_dat {
			pinmux = <PINMUX_GPIO14__FUNC_GPIO14>;
			slew-rate = <0>;
			bias-pull-down = <00>;
		};
	};
	charging_reset_active: charging_reset_active {
		pins_cmd_dat {
			pinmux = <PINMUX_GPIO21__FUNC_GPIO21>;
			slew-rate = <1>;
			output-high;
		};
	};
	charging_reset_sleep: charging_reset_sleep {
		pins_cmd_dat {
			pinmux = <PINMUX_GPIO21__FUNC_GPIO21>;
			slew-rate = <1>;
			output-low;
		};
	};
	vooc_asic_id_active: vooc_asic_id_active {
		pins_cmd_dat {
			pinmux = <PINMUX_GPIO73__FUNC_GPIO73>;
			input-enable;
			slew-rate = <0>;
			bias-pull-up;
		};
	};
	vooc_asic_id_sleep: vooc_asic_id_sleep {
		pins_cmd_dat {
			pinmux = <PINMUX_GPIO73__FUNC_GPIO73>;
			input-enable;
			slew-rate = <0>;
			bias-pull-down;
		};
	};
};
/*#include <oplus6781_20684/cust.dtsi>*/
/*#include "mediatek/cust_mt6781_camera.dtsi"*/
#include "mediatek/camera_ldo.dtsi"
#include "mediatek/cust_mt6781_camera_space.dtsi"
#include "mediatek/novatek-nt36xxx-spi.dtsi"
/*End of this file, DO NOT ADD ANYTHING HERE*/
